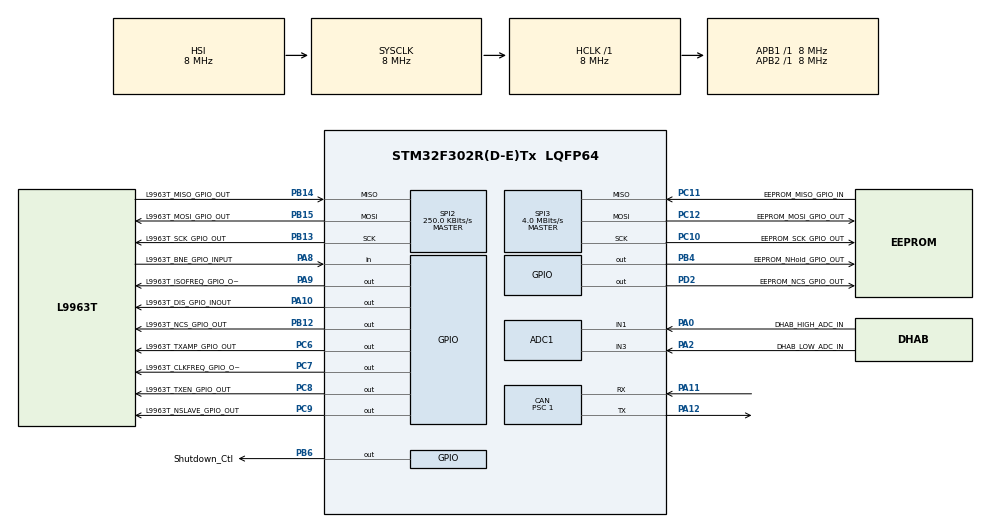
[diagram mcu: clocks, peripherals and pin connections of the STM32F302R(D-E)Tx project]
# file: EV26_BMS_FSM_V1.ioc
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ADC1.Channel-0\#ChannelRegularConversion=ADC_CHANNEL_1
ADC1.Channel-1\#ChannelRegularConversion=ADC_CHANNEL_3
ADC1.ContinuousConvMode=ENABLE
ADC1.DMAContinuousRequests=ENABLE
ADC1.NbrOfConversion=2
ADC1.NbrOfConversionFlag=1
ADC1.Offset-0\#ChannelRegularConversion=0
ADC1.Offset-1\#ChannelRegularConversion=0
ADC1.OffsetNumber-0\#ChannelRegularConversion=ADC_OFFSET_NONE
ADC1.OffsetNumber-1\#ChannelRegularConversion=ADC_OFFSET_NONE
ADC1.Rank-0\#ChannelRegularConversion=1
ADC1.Rank-1\#ChannelRegularConversion=2
ADC1.SamplingTime-0\#ChannelRegularConversion=ADC_SAMPLETIME_61CYCLES_5
ADC1.SamplingTime-1\#ChannelRegularConversion=ADC_SAMPLETIME_61CYCLES_5
ADC1.SamplingTimeOPAMP-1\#ChannelRegularConversion=ADC_SAMPLETIME_4CYCLES_5
ADC1.master=1
CAN.BS1=CAN_BS1_13TQ
CAN.BS2=CAN_BS2_2TQ
CAN.CalculateBaudRate=500000
CAN.CalculateTimeBit=2000
CAN.CalculateTimeQuantum=125.0
CAN.Prescaler=1
Dma.ADC1.0.Direction=DMA_PERIPH_TO_MEMORY
Dma.ADC1.0.Instance=DMA1_Channel1
Dma.ADC1.0.MemDataAlignment=DMA_MDATAALIGN_HALFWORD
Dma.ADC1.0.MemInc=DMA_MINC_ENABLE
Dma.ADC1.0.Mode=DMA_CIRCULAR
Dma.ADC1.0.PeriphDataAlignment=DMA_PDATAALIGN_HALFWORD
Dma.ADC1.0.PeriphInc=DMA_PINC_DISABLE
Dma.ADC1.0.Priority=DMA_PRIORITY_LOW
Dma.Request0=ADC1
Mcu.Family=STM32F3
Mcu.Name=STM32F302R(D-E)Tx
Mcu.Package=LQFP64
NVIC.DMA1_Channel1_IRQn=true\:1\:0\:true\:false\:true\:false\:true\:true
NVIC.PriorityGroup=NVIC_PRIORITYGROUP_4
PA0.GPIO_Label=DHAB_HIGH_ADC_IN
PA0.Mode=IN1-Single-Ended
PA0.Signal=ADC1_IN1
PA10.GPIO_Label=L9963T_DIS_GPIO_INOUT
PA10.Signal=GPIO_Output
PA11.Mode=CAN_Activate
PA11.Signal=CAN_RX
PA12.Mode=CAN_Activate
PA12.Signal=CAN_TX
PA13.Mode=JTAG_4_pins
PA13.Signal=SYS_JTMS-SWDIO
PA14.Mode=JTAG_4_pins
PA14.Signal=SYS_JTCK-SWCLK
PA15.Mode=JTAG_4_pins
PA15.Signal=SYS_JTDI
PA2.GPIO_Label=DHAB_LOW_ADC_IN
PA2.Mode=IN3-Single-Ended
PA2.Signal=ADC1_IN3
PA8.GPIO_Label=L9963T_BNE_GPIO_INPUT
PA8.Signal=GPIO_Input
PA9.GPIO_Label=L9963T_ISOFREQ_GPIO_OUT
PA9.Signal=GPIO_Output
PB12.GPIO_Label=L9963T_NCS_GPIO_OUT
PB12.Signal=GPIO_Output
PB13.GPIO_Label=L9963T_SCK_GPIO_OUT
PB13.Mode=Full_Duplex_Master
PB13.Signal=SPI2_SCK
PB14.GPIO_Label=L9963T_MISO_GPIO_OUT
PB14.Mode=Full_Duplex_Master
PB14.Signal=SPI2_MISO
PB15.GPIO_Label=L9963T_MOSI_GPIO_OUT
PB15.Mode=Full_Duplex_Master
PB15.Signal=SPI2_MOSI
PB3.Mode=JTAG_4_pins
PB3.Signal=SYS_JTDO-TRACESWO
PB4.GPIO_Label=EEPROM_NHold_GPIO_OUT
PB4.Signal=GPIO_Output
PB6.GPIO_Label=Shutdown_Ctl
PB6.Signal=GPIO_Output
PC10.GPIO_Label=EEPROM_SCK_GPIO_OUT
PC10.Mode=Full_Duplex_Master
PC10.Signal=SPI3_SCK
PC11.GPIO_Label=EEPROM_MISO_GPIO_IN
PC11.Mode=Full_Duplex_Master
PC11.Signal=SPI3_MISO
PC12.GPIO_Label=EEPROM_MOSI_GPIO_OUT
PC12.Mode=Full_Duplex_Master
PC12.Signal=SPI3_MOSI
PC6.GPIO_Label=L9963T_TXAMP_GPIO_OUT
PC6.Signal=GPIO_Output
PC7.GPIO_Label=L9963T_CLKFREQ_GPIO_OUT
PC7.Signal=GPIO_Output
PC8.GPIO_Label=L9963T_TXEN_GPIO_OUT
PC8.Signal=GPIO_Output
PC9.GPIO_Label=L9963T_NSLAVE_GPIO_OUT
PC9.GPIO_PuPd=GPIO_PULLDOWN
PC9.Signal=GPIO_Output
PD2.GPIO_Label=EEPROM_NCS_GPIO_OUT
PD2.Signal=GPIO_Output
ProjectManager.HeapSize=0x200
ProjectManager.StackSize=0x400
ProjectManager.TargetToolchain=CMake
RCC.AHBFreq_Value=8000000
RCC.APB1Freq_Value=8000000
RCC.APB2Freq_Value=8000000
RCC.CortexFreq_Value=8000000
RCC.HSE_VALUE=8000000
RCC.HSI_VALUE=8000000
RCC.LSE_VALUE=32768
RCC.PLLMUL=RCC_PLL_MUL4
RCC.SYSCLKFreq_VALUE=8000000
RCC.USBFreq_Value=32000000
SPI2.BaudRatePrescaler=SPI_BAUDRATEPRESCALER_32
SPI2.CLKPhase=SPI_PHASE_1EDGE
SPI2.CLKPolarity=SPI_POLARITY_HIGH
SPI2.CalculateBaudRate=250.0 KBits/s
SPI2.DataSize=SPI_DATASIZE_8BIT
SPI2.Direction=SPI_DIRECTION_2LINES
SPI2.Mode=SPI_MODE_MASTER
SPI2.VirtualType=VM_MASTER
SPI3.CalculateBaudRate=4.0 MBits/s
SPI3.DataSize=SPI_DATASIZE_8BIT
SPI3.Direction=SPI_DIRECTION_2LINES
SPI3.Mode=SPI_MODE_MASTER
SPI3.VirtualType=VM_MASTER
board=custom

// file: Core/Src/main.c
/* USER CODE BEGIN Header */
/**
  ******************************************************************************
  * @file           : main.c
  * @brief          : Main program body
  ******************************************************************************
  * @attention
  *
  * Copyright (c) 2026 STMicroelectronics.
  * All rights reserved.
  *
  * This software is licensed under terms that can be found in the LICENSE file
  * in the root directory of this software component.
  * If no LICENSE file comes with this software, it is provided AS-IS.
  *
  ******************************************************************************
  */
/* USER CODE END Header */
#include "main.h"
#include "adc.h"
#include "can.h"
#include "dma.h"
#include "spi.h"
#include "gpio.h"

/* USER CODE BEGIN Includes */
#include "L9963.h"
#include "CANMessages.h"

/* USER CODE END Includes */

void SystemClock_Config(void);

int main(void)
{

  /* MCU Configuration--------------------------------------------------------*/

  /* Reset of all peripherals, Initializes the Flash interface and the Systick. */
  HAL_Init();

  /* Configure the system clock */
  SystemClock_Config();

  /* Initialize all configured peripherals */
  MX_GPIO_Init();
  MX_DMA_Init();
  MX_ADC1_Init();
  MX_CAN_Init();
  MX_SPI2_Init();
  MX_SPI3_Init();
  /* USER CODE BEGIN 2 */

  L9963T_Init();
  L9963E_Init(1);
  /* USER CODE END 2 */

  /* Infinite loop */
  /* USER CODE BEGIN WHILE */
  while (1)
  {
    /*
    L9963E_Wakeup();
    HAL_Delay(100);
    */

    /* USER CODE END WHILE */

  }
}

void SystemClock_Config(void)
{
  RCC_OscInitTypeDef RCC_OscInitStruct = {0};
  RCC_ClkInitTypeDef RCC_ClkInitStruct = {0};
  RCC_PeriphCLKInitTypeDef PeriphClkInit = {0};

  /** Initializes the RCC Oscillators according to the specified parameters
  * in the RCC_OscInitTypeDef structure.
  */
  RCC_OscInitStruct.OscillatorType = RCC_OSCILLATORTYPE_HSI;
  RCC_OscInitStruct.HSIState = RCC_HSI_ON;
  RCC_OscInitStruct.HSICalibrationValue = RCC_HSICALIBRATION_DEFAULT;
  RCC_OscInitStruct.PLL.PLLState = RCC_PLL_ON;
  RCC_OscInitStruct.PLL.PLLSource = RCC_PLLSOURCE_HSI;
  RCC_OscInitStruct.PLL.PLLMUL = RCC_PLL_MUL4;
  RCC_OscInitStruct.PLL.PREDIV = RCC_PREDIV_DIV1;
  if (HAL_RCC_OscConfig(&RCC_OscInitStruct) != HAL_OK)
  {
    Error_Handler();
  }

  /** Initializes the CPU, AHB and APB buses clocks
  */
  RCC_ClkInitStruct.ClockType = RCC_CLOCKTYPE_HCLK|RCC_CLOCKTYPE_SYSCLK
                              |RCC_CLOCKTYPE_PCLK1|RCC_CLOCKTYPE_PCLK2;
  RCC_ClkInitStruct.SYSCLKSource = RCC_SYSCLKSOURCE_HSI;
  RCC_ClkInitStruct.AHBCLKDivider = RCC_SYSCLK_DIV1;
  RCC_ClkInitStruct.APB1CLKDivider = RCC_HCLK_DIV1;
  RCC_ClkInitStruct.APB2CLKDivider = RCC_HCLK_DIV1;

  if (HAL_RCC_ClockConfig(&RCC_ClkInitStruct, FLASH_LATENCY_0) != HAL_OK)
  {
    Error_Handler();
  }
  PeriphClkInit.PeriphClockSelection = RCC_PERIPHCLK_ADC12;
  PeriphClkInit.Adc12ClockSelection = RCC_ADC12PLLCLK_DIV1;
  if (HAL_RCCEx_PeriphCLKConfig(&PeriphClkInit) != HAL_OK)
  {
    Error_Handler();
  }
}

void Error_Handler(void)
{
  __disable_irq();
  while (1)
  {
  }
}
